# STM32U599 register map
File version: 1.0
CPU: CM33 r0p1, little endian, MPU, FPU, 4 interrupt priority bits
Registers are 32-bit, read-write, reset 0x0 unless marked. A register's access mark holds for its fields unless they carry their own. Offsets are from the block's base; [hi:lo] are bit positions; {n}, {i} and the like mark numbered series; 'fields as' and 'values as' point back to an identical list.

## I2C1 — Inter-integrated circuit
Base 0x40005400
Same registers: I2C2 0x40005800, I2C4 0x40008400, I2C5 0x40009800, I2C6 0x40009C00, I2C3 0x46002800, SEC_I2C1 0x50005400, SEC_I2C2 0x50005800, SEC_I2C4 0x50008400, SEC_I2C5 0x50009800, SEC_I2C6 0x50009C00, SEC_I2C3 0x56002800
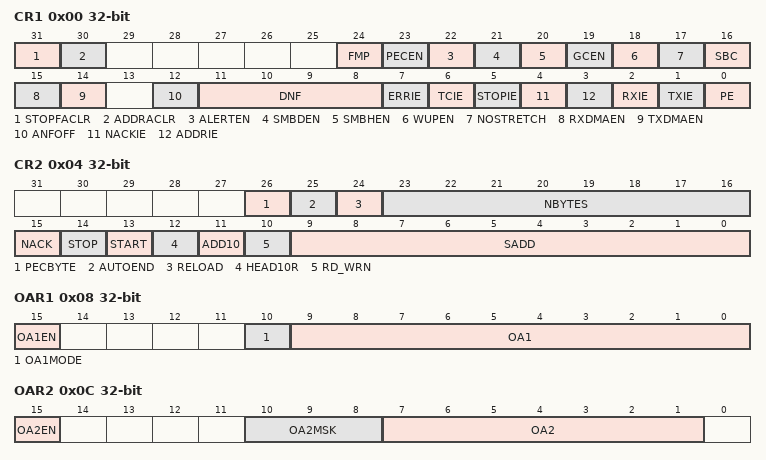
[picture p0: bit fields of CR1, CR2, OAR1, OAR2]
0x00 CR1 — Control register 1
  [31] STOPFACLR — STOP detection flag (STOPF) automatic clear
    0=Disabled (STOPF flag is set by hardware, cleared by software); 1=Enabled (STOPF flag remains cleared by hardware)
  [30] ADDRACLR — Address match flag (ADDR) automatic clear
    0=Disabled (ADDR flag is set by hardware, cleared by software); 1=Enabled (ADDR flag remains cleared by hardware)
  [24] FMP — Fast-mode Plus 20 mA drive enable
    0=Disabled (20 mA I/O drive disabled); 1=Enabled (20 mA I/O drive enabled)
  [23] PECEN — PEC enable
    0=Disabled (PEC calculation disabled); 1=Enabled (PEC calculation enabled)
  [22] ALERTEN — SMBUS alert enable
    0=Disabled (In device mode (SMBHEN=Disabled) Releases SMBA pin high and Alert Response Address Header disabled (0001100x) followed by NACK. In host mode (SMBHEN=Enabled) SMBus Alert pin (SMBA) not supported); 1=Enabled (In device mode (SMBHEN=Disabled) Drives SMBA pin low and Alert Response Address Header enabled (0001100x) followed by ACK.In host mode (SMBHEN=Enabled) SMBus Alert pin (SMBA) supported)
  [21] SMBDEN — SMBus Device Default address enable
    0=Disabled (Device default address disabled. Address 0b1100001x is NACKed); 1=Enabled (Device default address enabled. Address 0b1100001x is ACKed)
  [20] SMBHEN — SMBus Host address enable
    0=Disabled (Host address disabled. Address 0b0001000x is NACKed); 1=Enabled (Host address enabled. Address 0b0001000x is ACKed)
  [19] GCEN — General call enable
    0=Disabled (General call disabled. Address 0b00000000 is NACKed); 1=Enabled (General call enabled. Address 0b00000000 is ACKed)
  [18] WUPEN — Wakeup from STOP enable
    0=Disabled (Wakeup from Stop mode disabled); 1=Enabled (Wakeup from Stop mode enabled)
  [17] NOSTRETCH — Clock stretching disable
    0=Enabled (Clock stretching enabled); 1=Disabled (Clock stretching disabled)
  [16] SBC — Slave byte control
    0=Disabled (Slave byte control disabled); 1=Enabled (Slave byte control enabled)
  [15] RXDMAEN — DMA reception requests enable
    0=Disabled (DMA mode disabled for reception); 1=Enabled (DMA mode enabled for reception)
  [14] TXDMAEN — DMA transmission requests enable
    0=Disabled (DMA mode disabled for transmission); 1=Enabled (DMA mode enabled for transmission)
  [12] ANFOFF — Analog noise filter OFF
    0=Enabled (Analog noise filter enabled); 1=Disabled (Analog noise filter disabled)
  [11:8] DNF — Digital noise filter
    0=NoFilter (Digital filter disabled); {v}=Filter{v} (Digital filter enabled and filtering capability up to {v} tI2CCLK) (v=1..15)
  [7] ERRIE — Error interrupts enable
    0=Disabled (Error detection interrupts disabled); 1=Enabled (Error detection interrupts enabled)
  [6] TCIE — Transfer Complete interrupt enable
    0=Disabled (Transfer Complete interrupt disabled); 1=Enabled (Transfer Complete interrupt enabled)
  [5] STOPIE — STOP detection Interrupt enable
    0=Disabled (Stop detection (STOPF) interrupt disabled); 1=Enabled (Stop detection (STOPF) interrupt enabled)
  [4] NACKIE — Not acknowledge received interrupt enable
    0=Disabled (Not acknowledge (NACKF) received interrupts disabled); 1=Enabled (Not acknowledge (NACKF) received interrupts enabled)
  [3] ADDRIE — Address match interrupt enable (slave only)
    0=Disabled (Address match (ADDR) interrupts disabled); 1=Enabled (Address match (ADDR) interrupts enabled)
  [2] RXIE — RX Interrupt enable
    0=Disabled (Receive (RXNE) interrupt disabled); 1=Enabled (Receive (RXNE) interrupt enabled)
  [1] TXIE — TX Interrupt enable
    0=Disabled (Transmit (TXIS) interrupt disabled); 1=Enabled (Transmit (TXIS) interrupt enabled)
  [0] PE — Peripheral enable
    0=Disabled (Peripheral disabled); 1=Enabled (Peripheral enabled)
0x04 CR2 — Control register 2
  [26] PECBYTE write-1-sets — Packet error checking byte
    on read: 0=No PEC transfer; 1=Pec (PEC transmission/reception is requested) | on write: 1=Pec (PEC transmission/reception is requested)
  [25] AUTOEND — Automatic end mode (master mode)
    0=Software end mode: TC flag is set when NBYTES data are transferred, stretching SCL low; 1=Automatic end mode: a STOP condition is automatically sent when NBYTES data are transferred
  [24] RELOAD — NBYTES reload mode
    0=Completed (The transfer is completed after the NBYTES data transfer (STOP or RESTART will follow)); 1=NotCompleted (The transfer is not completed after the NBYTES data transfer (NBYTES will be reloaded))
  [23:16] NBYTES — Number of bytes
  [15] NACK write-1-sets — NACK generation (slave mode)
    on read: 0=Ack (an ACK is sent after current received byte); 1=Nack (a NACK is sent after current received byte) | on write: 1=Nack (a NACK is sent after current received byte)
  [14] STOP write-1-sets — Stop generation (master mode)
    on read: 0=No Stop generation; 1=Stop generation after current byte transfer | on write: 1=Stop generation after current byte transfer
  [13] START write-1-sets — Start generation
    on read: 0=No Start generation; 1=Start (Restart/Start generation) | on write: 1=Start (Restart/Start generation)
  [12] HEAD10R — 10-bit address header only read direction (master receiver mode)
    0=Complete (The master sends the complete 10 bit slave address read sequence); 1=Partial (The master only sends the 1st 7 bits of the 10 bit address, followed by Read direction)
  [11] ADD10 — 10-bit addressing mode (master mode)
    0=Bit7 (The master operates in 7-bit addressing mode); 1=Bit10 (The master operates in 10-bit addressing mode)
  [10] RD_WRN — Transfer direction (master mode)
    0=Write (Master requests a write transfer); 1=Read (Master requests a read transfer)
  [9:0] SADD — Slave address bit (master mode)
0x08 OAR1 — Own address register 1
  [15] OA1EN — Own Address 1 enable
    0=Disabled (Own address 1 disabled. The received slave address OA1 is NACKed); 1=Enabled (Own address 1 enabled. The received slave address OA1 is ACKed)
  [10] OA1MODE — Own Address 1 10-bit mode
    0=Bit7 (Own address 1 is a 7-bit address); 1=Bit10 (Own address 1 is a 10-bit address)
  [9:0] OA1 — Interface address
0x0C OAR2 — Own address register 2
  [15] OA2EN — Own Address 2 enable
    0=Disabled (Own address 2 disabled. The received slave address OA2 is NACKed); 1=Enabled (Own address 2 enabled. The received slave address OA2 is ACKed)
  [10:8] OA2MSK — Own Address 2 masks
    0=NoMask; 1=Mask1 (OA2[1] is masked and don’t care. Only OA2[7:2] are compared); {v}=Mask{v} (OA2[{v}:1] are masked and don’t care. Only OA2[7:{v+1}] are compared) (v=2..5); 6=Mask6 (OA2[6:1] are masked and don’t care. Only OA2[7] is compared.); 7=Mask7 (OA2[7:1] are masked and don’t care. No comparison is done, and all (except reserved) 7-bit received addresses are acknowledged)
  [7:1] OA2 — Interface address
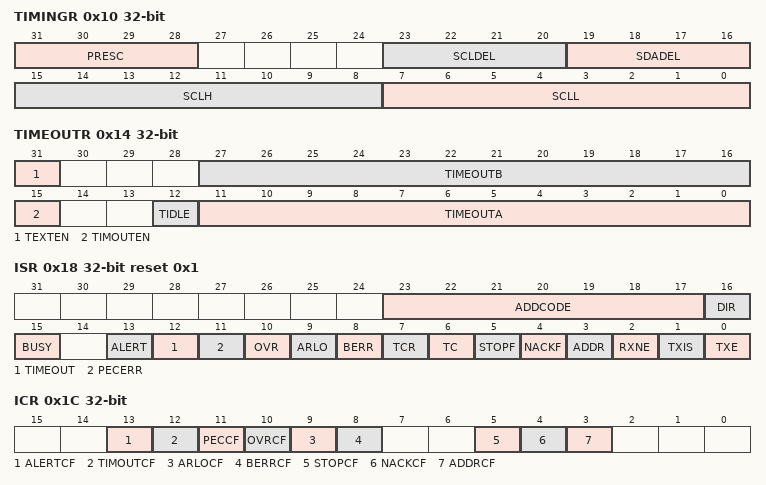
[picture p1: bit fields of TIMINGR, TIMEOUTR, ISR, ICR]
0x10 TIMINGR — Timing register
  [31:28] PRESC — Timing prescaler
  [23:20] SCLDEL — Data setup time
  [19:16] SDADEL — Data hold time
  [15:8] SCLH — SCL high period (master mode)
  [7:0] SCLL — SCL low period (master mode)
0x14 TIMEOUTR — Status register 1
  [31] TEXTEN — Extended clock timeout enable
    0=Disabled (Extended clock timeout detection is disabled); 1=Enabled (Extended clock timeout detection is enabled)
  [27:16] TIMEOUTB — Bus timeout B
  [15] TIMOUTEN — Clock timeout enable
    0=Disabled (SCL timeout detection is disabled); 1=Enabled (SCL timeout detection is enabled)
  [12] TIDLE — Idle clock timeout detection
    0=Disabled (TIMEOUTA is used to detect SCL low timeout); 1=Enabled (TIMEOUTA is used to detect both SCL and SDA high timeout (bus idle condition))
  [11:0] TIMEOUTA — Bus timeout A
0x18 ISR access per field reset 0x1 — Interrupt and Status register
  [23:17] ADDCODE ro — Address match code (Slave mode)
  [16] DIR ro — Transfer direction (Slave mode)
    0=Write transfer, slave enters receiver mode; 1=Read transfer, slave enters transmitter mode
  [15] BUSY ro — Bus busy
    0=NotBusy (No communication is in progress on the bus); 1=Busy (A communication is in progress on the bus)
  [13] ALERT ro — SMBus alert
    0=NoAlert (SMBA alert is not detected); 1=Alert (SMBA alert event is detected on SMBA pin)
  [12] TIMEOUT ro — Timeout or t_low detection flag
    0=No timeout occured; 1=Timeout occured
  [11] PECERR ro — PEC Error in reception
    0=Match (Received PEC does match with PEC register); 1=NoMatch (Received PEC does not match with PEC register)
  [10] OVR ro — Overrun/Underrun (slave mode)
    0=No overrun/underrun error occurs; 1=Overrun (slave mode with NOSTRETCH=1, when an overrun/underrun error occurs)
  [9] ARLO ro — Arbitration lost
    0=NotLost (No arbitration lost); 1=Lost (Arbitration lost)
  [8] BERR ro — Bus error
    0=NoError (No bus error); 1=Error (Misplaced Start and Stop condition is detected)
  [7] TCR ro — Transfer Complete Reload
    0=NotComplete (Transfer is not complete); 1=Complete (NBYTES has been transfered)
  [6] TC ro — Transfer Complete (master mode)
    values as TCR
  [5] STOPF ro — Stop detection flag
    0=No Stop condition detected; 1=Stop condition detected
  [4] NACKF ro — Not acknowledge received flag
    0=No NACK has been received; 1=NACK has been received
  [3] ADDR ro — Address matched (slave mode)
    0=NotMatch (Adress mismatched or not received); 1=Match (Received slave address matched with one of the enabled slave addresses)
  [2] RXNE ro — Receive data register not empty (receivers)
    0=Empty (The RXDR register is empty); 1=NotEmpty (Received data is copied into the RXDR register, and is ready to be read)
  [1] TXIS rw write-1-sets — Transmit interrupt status (transmitters)
    on read: 0=NotEmpty (The TXDR register is not empty); 1=Empty (The TXDR register is empty and the data to be transmitted must be written in the TXDR register) | on write: 1=Trigger (Generate a TXIS event)
  [0] TXE rw write-1-sets — Transmit data register empty (transmitters)
    on read: 0=NotEmpty (TXDR register not empty); 1=Empty (TXDR register empty) | on write: 1=Flush the transmit data register
0x1C ICR wo — Interrupt clear register
  [13] ALERTCF write-1-clears — Alert flag clear
    1=Clears the ALERT flag in ISR register
  [12] TIMOUTCF write-1-clears — Timeout detection flag clear
    1=Clears the TIMOUT flag in ISR register
  [11] PECCF write-1-clears — PEC Error flag clear
    1=Clears the PEC flag in ISR register
  [10] OVRCF write-1-clears — Overrun/Underrun flag clear
    1=Clears the OVR flag in ISR register
  [9] ARLOCF write-1-clears — Arbitration lost flag clear
    1=Clears the ARLO flag in ISR register
  [8] BERRCF write-1-clears — Bus error flag clear
    1=Clears the BERR flag in ISR register
  [5] STOPCF write-1-clears — Stop detection flag clear
    1=Clears the STOP flag in ISR register
  [4] NACKCF write-1-clears — Not Acknowledge flag clear
    1=Clears the NACK flag in ISR register
  [3] ADDRCF write-1-clears — Address Matched flag clear
    1=Clears the ADDR flag in ISR register
0x20 PECR ro — PEC register
  [7:0] PEC — Packet error checking register
0x24 RXDR ro — Receive data register
  [7:0] RXDATA — 8-bit receive data
0x28 TXDR — Transmit data register
  [7:0] TXDATA — 8-bit transmit data
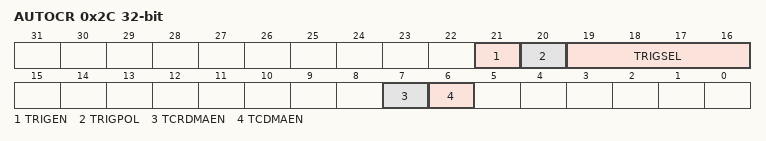
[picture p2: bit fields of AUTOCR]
0x2C AUTOCR — I2C Autonomous mode control register
  [21] TRIGEN — Trigger enable
  [20] TRIGPOL — Trigger polarity
  [19:16] TRIGSEL — Trigger selection
  [7] TCRDMAEN — DMA request enable on Transfer Complete Reload event
  [6] TCDMAEN — DMA request enable on Transfer Complete event
